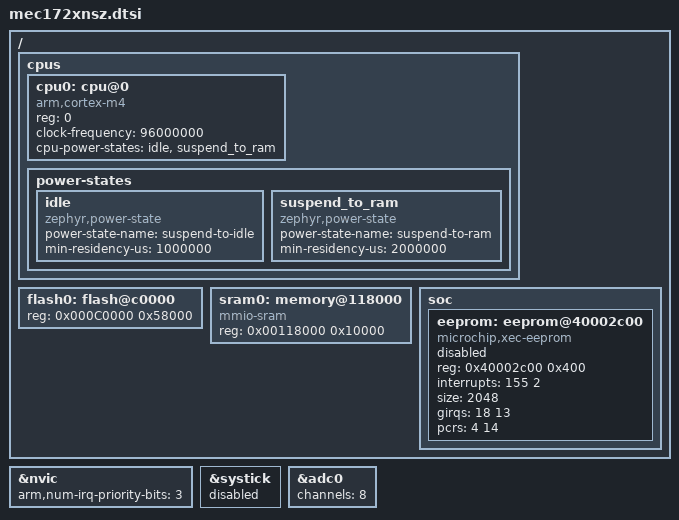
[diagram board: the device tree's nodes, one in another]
/*
 * Copyright (c) 2021 Microchip Technology Inc.
 *
 * SPDX-License-Identifier: Apache-2.0
 */

#include <arm/armv7-m.dtsi>

#include <zephyr/dt-bindings/adc/adc.h>
#include <zephyr/dt-bindings/clock/mchp_xec_pcr.h>
#include <zephyr/dt-bindings/gpio/gpio.h>
#include <zephyr/dt-bindings/gpio/microchip-xec-gpio.h>
#include <zephyr/dt-bindings/i2c/i2c.h>
#include <zephyr/dt-bindings/interrupt-controller/mchp-xec-ecia.h>
#include <freq.h>
#include <mem.h>

#include "mec172x/mec172x-vw-routing.dtsi"

/ {
	cpus {
		#address-cells = <1>;
		#size-cells = <0>;

		cpu0: cpu@0 {
			device_type = "cpu";
			compatible = "arm,cortex-m4";
			reg = <0>;
			clock-frequency = <96000000>;
			cpu-power-states = <&idle &suspend_to_ram>;
		};

		power-states {
			idle: idle {
				compatible = "zephyr,power-state";
				power-state-name = "suspend-to-idle";
				min-residency-us = <1000000>;
			};

			suspend_to_ram: suspend_to_ram {
				compatible = "zephyr,power-state";
				power-state-name = "suspend-to-ram";
				min-residency-us = <2000000>;
			};
		};
	};

	flash0: flash@c0000 {
		reg = <0x000C0000 0x58000>;
	};

	sram0: memory@118000 {
		compatible = "mmio-sram";
		reg = <0x00118000 0x10000>;
	};

	soc {
		#include "mec172x_common.dtsi"

		eeprom: eeprom@40002c00 {
			compatible = "microchip,xec-eeprom";
			reg = <0x40002c00 0x400>;
			interrupts = <155 2>;
			size = <2048>;
			girqs = <18 13>;
			pcrs = <4 14>;
			status = "disabled";
		};
	};
};

&nvic {
	arm,num-irq-priority-bits = <3>;
};

&systick {
	status = "disabled";
};

&adc0 {
	channels = <8>;
};
